AUTOSAR XML (schema 4-2-2)
package /AUTOLIV/SoftwareComponents/FSM
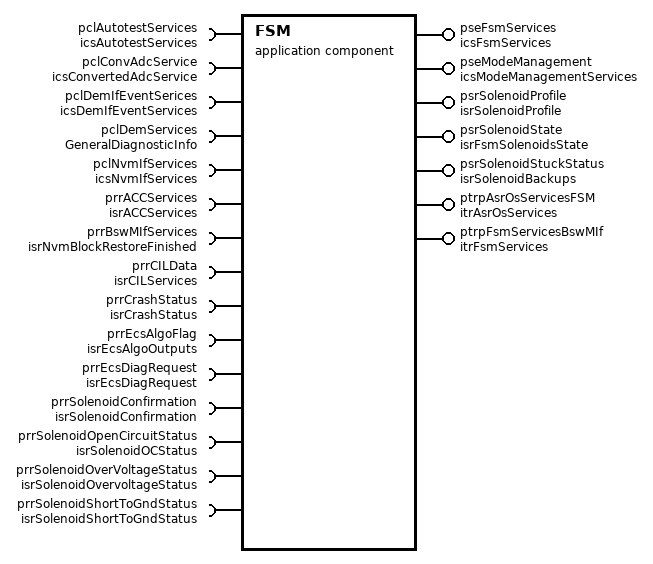
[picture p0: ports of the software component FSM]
  application sw component type FSM: category=SWC
    15 x require port:
      pclAutotestServices: required-com-specs=[GetCriticalAutoTestsReachedFlag, GetTestResult], required-interface=icsAutotestServices  # # Architecture Element ID ARCH_SW_FSM_pclAutotestServices # Description - The interface shall be used to read if the last critical auto-test has been run # Data Flow ## Inputs ## Outputs - {Last Critical Auto-test Status} #Linked Runnable - FSM_runUpdateModeStatus # Traceability
      pclConvAdcService: client-com-spec=getMeasure, required-interface=icsConvertedAdcService  # # Architecture Element ID ARCH_SW_FSM_pclConvAdcService # Description - Interface is used to read physical measurements in SI units - Interface will be used to read the voltage (mV) for the KL30 supply # Data Flow ## Inputs: ## Outputs: - {SI Measurement} # Linked Runnable - FSM_runMainFunction # Traceability
      pclDemIfEventSerices: client-com-spec=GetCounterPassedThreshold, required-interface=icsDemIfEventServices  # # Architecture Element ID ARCH_SW_FSM_pclDemIfEventSerices # Description - Interface is used to read the counter value which should be reached in order to set the event as PASSED; - Interface will provide the {Event_ID} as input and will retrieve the {Counter_Value} of the corresponding event; # Data Flow ## Inputs: - {Event_ID}: The ID of event; ## Outputs: - {Counter_Value}: value of the Pass confirmation counter; # Linked Runnable - FSM_runMainFunction # Traceability
      pclDemServices: required-interface=GeneralDiagnosticInfo  # # Architecture Element ID ARCH_SW_FSM_pclDemServices # Description - The interface shall be used to read the {Event Status} of a Dem event for the selected {Event Id} # Data Flow ## Inputs - {Event Id} ## Outputs - {Event Status} #Linked Runnable - FSM_runUpdateModeStatus # Traceability DOM_eCS_TF_R_12, DOM_eCS_TF_R_13, DOM_eCS_TF_R_49, DOM_eCS_TF_R_48, DOM_eCS_TF_R_50, DOM_eCS_TF_R_51, DOM_eCS_TF_R_52, DOM_eCS_TF_R_56, DOM_eCS_TF_R_54
        required-com-specs:
          GetEventStatus
          GetEventFailed
          GetEventTested
          GetDTCOfEvent
          GetFaultDetectionCounter
          GetEventFreezeFrameData
          GetEventExtendedDataRecord
          GetDebouncingOfEvent
          GetEventExtendedDataRecordEx
          GetEventFreezeFrameDataEx
      pclNvmIfServices: required-interface=icsNvmIfServices  # # Architecture Element ID ARCH_SW_FSM_pseNvmIfServices_FSM_manageSolenoidCounters # Description - The runnable will pass the {Block Status} from the input parameter for the selected {Block Id} # Data Flow ## Inputs - {Block Id} - {Block Status} - Can be TRUE, FALSE ## Outputs # Linked Runnable - FSM_runMainFunction #Traceability
        required-com-specs:
          GetNvmBlockLength
          GetNvmBlockStatus
          ReadBlockByAddress
          RestorePRAMBlockDefaults
          SetRamBlockStatus
          WriteBlockByAddress
          WriteNvmBlock
      prrACCServices: nonqueued-receiver-com-spec{data-element=u8AccInitStateMachine, init-value=0}, required-interface=isrACCServices  # # Architecture Element ID ARCH_SW_FSM_prrACCServices # Description - The interface shall be used to read the initialization phase status of the accelerometer by saving the value in {Block Restore Status} output variable. # Data Flow ## Inputs ## Outputs - {Block Restore Status} #Linked Runnable - FSM_runUpdateModeStatus # Traceability
      prrBswMIfServices: nonqueued-receiver-com-spec{data-element=u8BlockRestoreStatus, init-value=B_FALSE:85}, required-interface=isrNvmBlockRestoreFinished  # # Architecture Element ID ARCH_SW_FSM_prrBswMIfServices # Description - The interface shall be used to read the NvM block restore status from the BswMIf module # Data Flow ## Inputs ## Outputs - {Block Restore Status} #Linked Runnable - FSM_runUpdateModeStatus # Traceability
      prrCILData: nonqueued-receiver-com-spec{data-element=au8MergedBuckleStatus, init-value=6 x 1}, required-interface=isrCILServices  # # Architecture Element ID ARCH_SW_Fsm_prrCILData_FSM_runUpdateModeStatus # Description - The interface shall be used to read the buckle status # Data Flow ## Inputs: ## Outputs - data (unsigned char *) - Can be KU8_BUCKLE_LATCHED/KU8_BUCKLE_NOT_LATCHED # Linked Runnable - FSM_runUpdateModeStatus # Traceability
      prrCrashStatus: nonqueued-receiver-com-spec{data-element=u8IsCrashActive, enable-update=true, init-value=CM_AB_Crash_Int_Cx0_kein_Crash}, required-interface=isrCrashStatus  # # Architecture Element ID ARCH_SW_FSM_prrCrashStatus # Description - The interface shall be used to read the the crash status that is reported on the CAN bus # Data Flow ## Inputs ## Outputs - {Crash Status} #Linked Runnable - FSM_runUpdateModeStatus # Traceability
      prrEcsAlgoFlag: required-interface=isrEcsAlgoOutputs  # # Architecture Element ID ARCH_SW_FSM_prrEcsAlgoFlag # Description - The interface shall be used to read the virtual ball algorithm output that will be used to compute the solenoid command # Data Flow ## Inputs ## Outputs - {Ball Algorithm Output} #Linked Runnable - FSM_runMainFunction # Traceability
        required-com-specs:
          data-element=u8EcsFlag, enable-update=true, init-value=KU8_ECS_ALGO_LOCK
          data-element=u16BallPosition, init-value=0
      prrEcsDiagRequest: required-interface=isrEcsDiagRequest  # prrEcsDiagnosticRequest | # Architecture Element ID ARCH_SW_FSM_prrEcsDiagRequest # Description - The runnable shall read the diagnostic request for the {Solenoid Command} - The runnable shall read the diagnostic request complement(mirror) for the {Solenoid Command} # Data Flow ## Inputs - {Solenoid Command} • Can take the values: - NO_DIAG_REQUEST - UNLOCK_DIAG_REQUES - LOCK_DIAG_REQUES; - PROFILE_REQUEST_ON; - PROFILE_REQUEST_OFF #Linked Runnable - FSM_runMainFunction # Traceability
        required-com-specs:
          data-element=au8DiagReq, enable-update=true, init-value=6 x KU8_NO_DIAG_REQUEST
          data-element=au8DiagReqComplement, enable-update=true, init-value=6 x 255
      prrSolenoidConfirmation: nonqueued-receiver-com-spec{data-element=au8SolenoidStatus, init-value=6 x KU8_SOLENOID_UNLOCK_NOT_CONFIRMED}, required-interface=isrSolenoidConfirmation  # # Architecture Element ID ARCH_SW_FSM_prrSolenoidConfirmation # Description - The interface shall be used to read if the solenoid lever has reached the unlock position # Data Flow ## Inputs ## Outputs - {Solenoid Confirmation 1} - {Solenoid Confirmation 2} - {Solenoid Confirmation 3} - {Solenoid Confirmation 4} - {Solenoid Confirmation 5} - {Solenoid Confirmation 6} #Linked Runnable - FSM_runUpdateModeStatus # Traceability
      prrSolenoidOpenCircuitStatus: nonqueued-receiver-com-spec{data-element=au8SolenoidAutotestStatus, enable-update=true, init-value=6 x KU8_SOLENOID_ELECTRICAL_AT_PASSED}, required-interface=isrSolenoidOCStatus  # # Architecture Element ID ARCH_SW_FSM_prrSolenoidOpenCircuitStatus # Description - Interface used to read the open circuit status for individual solenoids; # Data Flow ## Inputs ## Outputs - {Solenoid 1 Open Circuit status} - {Solenoid 2 Open Circuit status} - {Solenoid 3 Open Circuit status} - {Solenoid 4 Open Circuit status} - {Solenoid 5 Open Circuit status} - {Solenoid 6 Open Circuit status} #Linked Runnable - FSM_runUpdateModeStatus # Traceability
      prrSolenoidOverVoltageStatus: nonqueued-receiver-com-spec{data-element=au8SolenoidOvervoltageStatus, enable-update=true, init-value=6 x KU8_SOLENOID_ELECTRICAL_AT_PASSED}, required-interface=isrSolenoidOvervoltageStatus  # # Architecture Element ID ARCH_SW_FSM_prrSolenoidOverVoltageStatus # Description - The runnable shall read the array of {Status of solenoids} representing the error status regarding a Over Voltage fault for each solenoid. # Data Flow ## Inputs - {Status of solenoids} (valid for all solenoids) - Can be : - 00h - KU8_SOLENOID_ELECTRICAL_AT_PASSED - 01h - KU8_SOLENOID_ELECTRICAL_AT_FAILED ## Outputs - None #Linked Runnable - FSM_runUpdateModeStatus # Traceability
      prrSolenoidShortToGndStatus: nonqueued-receiver-com-spec{data-element=au8SolenoidAutotestStatus, enable-update=true, init-value=6 x KU8_SOLENOID_ELECTRICAL_AT_PASSED}, required-interface=isrSolenoidShortToGndStatus  # # Architecture Element ID ARCH_SW_FSM_prrSolenoidShortToGndStatus # Description - Interface used to read the Short to Ground status for individual solenoids; # Data Flow ## Inputs ## Outputs - {Solenoid 1 Short to ground status} - {Solenoid 2 Short to ground status} - {Solenoid 3 Short to ground status} - {Solenoid 4 Short to ground status} - {Solenoid 5 Short to ground status} - {Solenoid 6 Short to ground status} #Linked Runnable - FSM_runUpdateModeStatus # Traceability
    7 x provide port:
      pseFsmServices: provided-interface=icsFsmServices  # # Architecture Element ID ARCH_SW_FSM_pseFsmServices_FSM_getUnlockDetectionTimeoutPeriod # Description - The runnable shall be called by the function IoHwAb_DetectVoltageFluctuation # Data Flow ## Inputs ## Outputs - pu16UnlockDetectionTimeoutPeriod: Outputs the unlock detection timeout period. #Linked Runnable - FSM_getUnlockDetectionTimeoutPeriod # Traceability --------------------------------------------------------------------------------------------------------------------------------- # Architecture Element ID ARCH_SW_FSM_pseFsmServices_FSM_runCalculateProfileTimeout # Description - The runnable shall be called by the function DIDs FDE3 FDE4 # Data Flow ## Inputs ## Outputs - pu8Response: Outputs the status of profile timeout computation. #Linked Runnable - FSM_runCalculateProfileTimeout # Traceability ---------------------------------------------------------------------------------------------------------------------------------
        provided-com-specs:
          operation=calculateProfileTimeout, queue-length=1
          operation=getUnlockTimeoutPeriod, queue-length=1
      pseModeManagement: server-com-spec{operation=CheckModeStatus, queue-length=1}, provided-interface=icsModeManagementServices  # # Architecture Element ID ARCH_SW_FSM_pseModeManagement_CriticalAutotests # Description - The FSM_runUpdateModeStatus runnable shall set the mode status to TRUE for: The CRITICAL_AUTOTESTS_IN_PROGRESS flag if the last autotest has not beem run - The FSM_runCheckModeStatus shall report the {Mode Status} on the output parameter if the CRITICAL_AUTOTESTS_IN_PROGRESS is specified in the {Mode Flag} input parameter # Data Flow ## Inputs - {Mode Flag} ## Outputs - {Mode Status} - Can be TRUE, FALSE #Linked Runnable - FSM_runUpdateModeStatus - FSM_runCheckModeStatus # Traceability ------------------------------------------------------------------------------------------------------------------------------- # Architecture Element ID ARCH_SW_FSM_pseModeManagement_NvmBlockRestore # Description - The FSM_runUpdateModeStatus runnable shall set the mode status to TRUE for: - The NVM_BLOCK_RESTORE_IN_PROGRESS flag if during the initialization a restore has been triggered - The FSM_runCheckModeStatus shall report the {Mode Status} on the output parameter if the NVM_BLOCK_RESTORE_IN_PROGRESS is specified in the {Mode Flag} input parameter # Data Flow ## Inputs - {Mode Flag} ## Outputs - {Mode Status} - Can be TRUE, FALSE #Linked Runnable - FSM_runUpdateModeStatus - FSM_runCheckModeStatus # Traceability ------------------------------------------------------------------------------------------------------------------------------- # Architecture Element ID ARCH_SW_FSM_pseModeManagement_SolenoidDisabled # Description - The FSM_runUpdateModeStatus runnable shall set the mode status to TRUE for: - The SOLENOID_x_DISABLED (for each solenoid) if the UV/OV/NVM_NOT_PROG/ADC_OUT_OF_ORDER events are qualified - The FSM_runCheckModeStatus shall report the {Mode Status} on the output parameter if the SOLENOID_x_DISABLED is specified in the {Mode Flag} input parameter # Data Flow ## Inputs - {Mode Flag} ## Outputs - {Mode Status} - Can be TRUE, FALSE #Linked Runnable - FSM_runUpdateModeStatus - FSM_runCheckModeStatus # Traceability ------------------------------------------------------------------------------------------------------------------------------- # Architecture Element ID ARCH_SW_FSM_pseModeManagement_CanInhibStatus # Description - The FSM_runUpdateModeStatus runnable shall set the mode status to TRUE for: - The SOLENOID_x_CAN_INHIB_STATUS (for each solenoid) ifthe crash status received from the CAN bus is active - The FSM_runCheckModeStatus shall report the {Mode Status} on the output parameter if the SOLENOID_x_CAN_INHIB_STATUS is specified in the {Mode Flag} input parameter # Data Flow ## Inputs - {Mode Flag} ## Outputs - {Mode Status} - Can be TRUE, FALSE #Linked Runnable - FSM_runUpdateModeStatus - FSM_runCheckModeStatus # Traceability ------------------------------------------------------------------------------------------------------------------------------- # Architecture Element ID ARCH_SW_FSM_pseModeManagement_SolenoidUnlockConfirmation # Description - The FSM_runUpdateModeStatus runnable shall set the mode status to TRUE for: - The SOLENOID_x_UNLOCK_CONFIRMED (for each solenoid) ifthe solenoid lever has reached the unlock position - The FSM_runCheckModeStatus shall report the {Mode Status} on the output parameter if the SOLENOID_x_UNLOCK_CONFIRMED is specified in the {Mode Flag} input parameter # Data Flow ## Inputs - {Mode Flag} ## Outputs - {Mode Status} - Can be TRUE, FALSE #Linked Runnable - FSM_runUpdateModeStatus - FSM_runCheckModeStatus # Traceability ------------------------------------------------------------------------------------------------------------------------------- # Architecture Element ID ARCH_SW_FSM_pseModeManagement_EcuPermanentHwError # Description - The FSM_runUpdateModeStatus runnable shall set the mode status to TRUE for: - The ECU_PERMANENT_HW_ERROR if the RAM_ECC/NVM_ECC/FLS_ECC/ADC_OUT_OF_ORDER events are qualified - The FSM_runCheckModeStatus shall report the {Mode Status} on the output parameter if the ECU_PERMANENT_HW_ERROR is specified in the {Mode Flag} input parameter # Data Flow ## Inputs - {Mode Flag} ## Outputs - {Mode Status} - Can be TRUE, FALSE #Linked Runnable - FSM_runUpdateModeStatus - FSM_runCheckModeStatus # Traceability ------------------------------------------------------------------------------------------------------------------------------- # Architecture Element ID ARCH_SW_FSM_pseModeManagement_EcuSporadicError # Description - The FSM_runUpdateModeStatus runnable shall set the mode status to TRUE for: - The ECU_SPORADIC_ERROR if the UV/OV/NVM_NOT_PROG events are qualified - The FSM_runCheckModeStatus shall report the {Mode Status} on the output parameter if the ECU_SPORADIC_ERROR is specified in the {Mode Flag} input parameter # Data Flow ## Inputs - {Mode Flag} ## Outputs - {Mode Status} - Can be TRUE, FALSE #Linked Runnable - FSM_runUpdateModeStatus - FSM_runCheckModeStatus # Traceability ------------------------------------------------------------------------------------------------------------------------------- # Architecture Element ID ARCH_SW_FSM_pseModeManagement_BuckleStatus # Description - The FSM_runUpdateModeStatus runnable shall set the mode status to TRUE for: - The SOLENOID_BUCKLE_LATCHED if the seatbelt corresponding to an individual solenoid is connected to the bucke. - The FSM_runCheckModeStatus shall report the {Mode Status} on the output parameter if the SOLENOID_BUCKLE_LATCHED is specified in the {Mode Flag} input parameter. # Data Flow ## Inputs - {Mode Flag} ## Outputs - {Mode Status} - Can be TRUE, FALSE #Linked Runnable - FSM_runUpdateModeStatus - FSM_runCheckModeStatus # Traceability
      psrSolenoidProfile: nonqueued-sender-com-spec{data-element=au8SelectedProfile, uses-end-to-end-protection=0, init-value=6 x KU8_PROFILE_UNLOCK}, provided-interface=isrSolenoidProfile  # # Architecture Element ID ARCH_SW_FSM_psrSolenoidProfile_FSM_runMainFunction # Description - The runnable shall output the profile(collection of steps) nb. that should be executed by the SAD module for each solenoid. # Data Flow ## Inputs ## Outputs - {Profile for Solenoid x} (valid for all solenoids) - Can be - 00h - UNLOCK, - 01h - BACKUP - FFh - NO_PROFILE #Linked Runnable - FSM_runMainFunction # Traceability
      psrSolenoidState: nonqueued-sender-com-spec{data-element=au8SolenoidState, uses-end-to-end-protection=0, init-value=6 x KU8_LOCK_STATE}, provided-interface=isrFsmSolenoidsState  # # Architecture Element ID ARCH_SW_FSM_psrSolenoidState_FSM_runMainFunction # Description - The runnable shall output the current solenoid actuator state # Data Flow ## Inputs ## Outputs - {State for Solenoid x} (valid for all solenoids) - Can be - 00h - LOCK - 01h - UNLOCK - 02h - BACKUP - 03h - DISABLED - 04h - ERROR - 04h - STARTUP - 06h - DIAGNOSTIC #Linked Runnable - FSM_runMainFunction # Traceability
      psrSolenoidStuckStatus: nonqueued-sender-com-spec{data-element=au8SolenoidIsStuck, uses-end-to-end-protection=0, init-value=6 x 0}, provided-interface=isrSolenoidBackups  # # Architecture Element ID ARCH_SW_FSM_psrSolenoidStuckStatus_FSM_runMainFunction # Description - The runnable shall output on {Solenoid Stuck Status} the current state of each solenoid, based on the number of retries when the backup profile is active. - When the retry counter is equal to NVP_u8NbOfBackups then the auto-test shall be failed # Data Flow ## Inputs ## Outputs - {Solenoid Stuck Status} - Can be KU8_FALSE - if the solenoid is NOT stuck; - Can be KU8_TRUE - if the solenoid is stuck; #Linked Runnable - FSM_runMainFunction # Traceability DOM_eCS_TF_H_234, DOM_eCS_TF_H_235
      ptrpAsrOsServicesFSM: provided-interface=itrAsrOsServices  # # Architecture Element ID ARCH_SW_FSM_ptrpAsrOsServices_FSM_runMainFunction # Description - The runnable shall be called by the Autosar OS each 1mS; # Data Flow ## Inputs ## Outputs #Linked Runnable - FSM_runMainFunction # Traceability FUSA_SM_S32K1XXSM_59, FUSA_SM_S32K1XXSM_128, FUSA_SM_S32K1XXSM_132, FUSA_SM_S32K1XXSM_148, DOM_eCS_TF_R_159, DOM_eCS_TF_R_160, DOM_eCS_TF_R_83, DOM_eCS_TF_R_85, DOM_eCS_TF_R_177, DOM_eCS_TF_R_79, DOM_eCS_TF_R_172, DOM_eCS_TF_R_81, DOM_eCS_TF_R_91, DOM_eCS_TF_R_92, DOM_eCS_TF_R_93, DOM_eCS_TF_R_108, DOM_eCS_TF_R_107, DOM_eCS_TF_R_106, DOM_eCS_TF_R_105, DOM_eCS_TF_R_104, DOM_eCS_TF_R_103, DOM_eCS_TF_R_102, DOM_eCS_TF_R_101, DOM_eCS_TF_R_100, DOM_eCS_TF_R_99, DOM_eCS_TF_R_98, DOM_eCS_TF_R_97, DOM_eCS_TF_R_96, DOM_eCS_TF_R_95, DOM_eCS_TF_R_94, DOM_eCS_TF_R_200, DOM_eCS_TF_R_204 --------------------------------------------------------------------------------------------------------------------------------- # Architecture Element ID ARCH_SW_FSM_ptrpAsrOsServices_FSM_runMainFunction_Start # Description - At the START (before calling the runnable the first time) the interlocking mechanism of the solenoids will not be accessible; - After START, if the INIT phase is not finished, the solenoids will be put in LOCK state; - After START, solenoids that are unconfigured in NVP, will be put in DISABLED state; - After START, if a FAIL condition appears, the solenoids will be put in DISABLED state ; - After START, if the command is LOCK and no fails are detected the solenoids will be put in LOCK state; - After START, if the command is UNLOCK and no fails are detected the solenoids will be put in UNLOCK state; # Data Flow ## Inputs ## Outputs #Linked Runnable - FSM_runMainFunction # Traceability DOM_eCS_TF_R_78; DOM_eCS_TF_R_185; DOM_eCS_TF_R_183; DOM_eCS_TF_R_184; DOM_eCS_TF_R_185; --------------------------------------------------------------------------------------------------------------------------------- # Architecture Element ID ARCH_SW_FSM_ptrpAsrOsServices_FSM_runMainFunction_DIagnostic # Description - When DIAGNOSTIC state is active for a solenoid, no INTERLOCKING will be possible; - Transition DIAGNOSTIC - LOCK will be done after DIAGNOSTIC is finished and if the command is LOCK and no FAILS are detected; - Transition DIAGNOSTIC - UNLOCK will be done after DIAGNOSTIC is finished and if the command is UNLOCK and no FAILS are detected; - Transition DIAGNOSTIC - DISABLE will be done if at least one relevant auto-test is FAIL; # Data Flow ## Inputs ## Outputs #Linked Runnable - FSM_runMainFunction # Traceability DOM_eCS_TF_R_168; DOM_eCS_TF_R_170; DOM_eCS_TF_R_180; DOM_eCS_TF_R_192; DOM_eCS_TF_R_193; --------------------------------------------------------------------------------------------------------------------------------- # Architecture Element ID ARCH_SW_FSM_ptrpAsrOsServices_FSM_runMainFunction_Startup # Description - Transition STARTUP - LOCK will be done after STURTUP is finished and if the command is LOCK and no FAILS are detected; - Transition STARTUP - UNLOCK will be done after STURTUP is finished and if the command is UNLOCK and no FAILS are detected; - Transition STARTUP - UNLOCK - BACKUP will be done after STURTUP is finished and if the command is UNLOCK can't be confirmed and no FAILS are detected; - Transition STARTUP - DISABLE will be done if at least one relevant auto-test is FAIL; # Data Flow ## Inputs ## Outputs #Linked Runnable - FSM_runMainFunction # Traceability DOM_eCS_TF_R_171; DOM_eCS_TF_R_179; DOM_eCS_TF_R_187; DOM_eCS_TF_R_188; DOM_eCS_TF_R_189; --------------------------------------------------------------------------------------------------------------------------------- # Architecture Element ID ARCH_SW_FSM_ptrpAsrOsServices_FSM_runMainFunction_Lock # Description - LOCK state will be maintained for as long as the command is LOCK and no FAILS are detected; - Transition LOCK - UNLOCK will be done if the command is UNLOCK and no FAILS are detected; - Transition LOCK - DIAGNOSTIC will be done after critical auto-tests are finished; - Transition LOCK - DISABLE will be done if at least one relevant auto-test is FAIL; # Data Flow ## Inputs ## Outputs #Linked Runnable - FSM_runMainFunction # Traceability DOM_eCS_TF_R_78; DOM_eCS_TF_R_80; DOM_eCS_TF_R_178; DOM_eCS_TF_R_186; FUSA_SM_S32K1XXSM_148, FUSA_SM_S32K1XXSM_59, FUSA_SM_S32K1XXSM_128; --------------------------------------------------------------------------------------------------------------------------------- # Architecture Element ID ARCH_SW_FSM_ptrpAsrOsServices_FSM_runMainFunction_Unlock # Description - When DISABLE state is active for a solenoid, INTERLOCKING will be possible; - Transition UNLOCK - LOCK will be done if the command is LOCK and no FAILS are detected; - UNLOCK state will remain if the command is UNLOCK and be confirmed and no FAILS are detected; - Transition UNLOCK - BACKUP will be done if the command is UNLOCK can't be confirmed and no FAILS are detected; - Transition UNLOCK - DISABLE will be done if at least one relevant auto-test is FAIL; # Data Flow ## Inputs ## Outputs #Linked Runnable - FSM_runMainFunction # Traceability DOM_eCS_TF_R_82; DOM_eCS_TF_R_82; DOM_eCS_TF_R_86; DOM_eCS_TF_R_88; DOM_eCS_TF_R_190; DOM_eCS_TF_R_191; --------------------------------------------------------------------------------------------------------------------------------- # Architecture Element ID ARCH_SW_FSM_ptrpAsrOsServices_FSM_runMainFunction_Backup # Description - When BACKUP state is active for a solenoid, INTERLOCKING will be possible; - BACKUP state will remain if the command is BACKUP and unlock can't be confirmed and no FAILS are detected; - Transition BACKUP - LOCK will be done if the command is LOCK and no FAILS are detected; - Transition BACKUP - DISABLE will be done if at least one relevant auto-test is FAIL; # Data Flow ## Inputs ## Outputs #Linked Runnable - FSM_runMainFunction # Traceability DOM_eCS_TF_R_169; DOM_eCS_TF_R_181; DOM_eCS_TF_R_182; DOM_eCS_TF_R_194; DOM_eCS_TF_R_195; --------------------------------------------------------------------------------------------------------------------------------- # Architecture Element ID ARCH_SW_FSM_ptrpAsrOsServices_FSM_runMainFunction_Disable # Description - When DISABLE state is active for a solenoid, no INTERLOCKING will be possible; - Transition DISABLE - LOCK will be done after all relevant auto-tests are PASSED and if the command is LOCK; - Transition DISABLE - UNLOCK will be done after all relevant auto-tests are PASSED and if the command is UNLOCK; # Data Flow ## Inputs ## Outputs #Linked Runnable - FSM_runMainFunction # Traceability DOM_eCS_TF_R_89; DOM_eCS_TF_R_196; DOM_eCS_TF_R_197; --------------------------------------------------------------------------------------------------------------------------------- # Architecture Element ID ARCH_SW_FSM_ptrpAsrOsServices_FSM_runUpdateModeStatus # Description - The runnable shall be called by the Autosar OS each 10ms # Data Flow ## Inputs ## Outputs #Linked Runnable - FSM_runUpdateModeStatus # Traceability FUSA_SM_S32K1XXSM_59, FUSA_SM_S32K1XXSM_128, FUSA_SM_S32K1XXSM_132, FUSA_SM_S32K1XXSM_148
      ptrpFsmServicesBswMIf: provided-interface=itrFsmServices  # # Architecture Element ID ARCH_SW_Fsm_ptrpFsmServicesBswMIf_FSM_Init # Description - The FSM_Init runnable shall be called during the initialization in the BswM_OnStartupTwoB runnable # Data Flow # Linked Runnable - FSM_Init # Traceability ---------------------------------------------------------------------------------------------------------------------------- # Architecture Element ID ARCH_SW_Fsm_ptrpFsmServicesBswMIf_FSM_ModesInit # Description - The FSM_ModesInit runnable shall be called during the initialization in the BswM_OnStartComEffective runnable # Data Flow # Linked Runnable - FSM_ModesInit # Traceability FUSA_SM_S32K1XXSM_452
  client server interface icsFsmServices
    operation calculateProfileTimeout
      arg pu8Response: type=uint8, direction=OUT, server-argument-impl-policy=USE-ARGUMENT-TYPE
    operation getUnlockTimeoutPeriod
      arg pu16UnlockDetectionTimeoutPeriod: type=uint16, direction=OUT, server-argument-impl-policy=USE-ARGUMENT-TYPE
